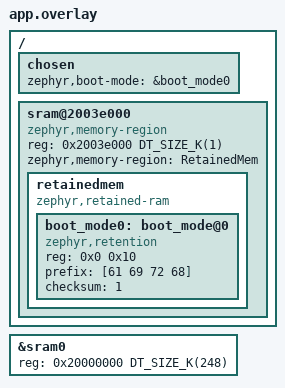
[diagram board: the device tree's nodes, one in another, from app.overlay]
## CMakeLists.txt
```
# SPDX-License-Identifier: Apache-2.0
cmake_minimum_required(VERSION 3.20.0)

find_package(Zephyr REQUIRED HINTS $ENV{ZEPHYR_BASE})
project(airhand)

target_sources(app PRIVATE src/main.c src/proto.c)
target_compile_definitions(app PRIVATE PROTO_VERSION="${APP_VERSION_STRING}")
```

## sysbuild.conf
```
SB_CONFIG_BOOTLOADER_MCUBOOT=y
SB_CONFIG_MCUBOOT_MODE_SWAP_USING_MOVE=y
# Anyone with the USB port can already flash the dongle, so a key adds no protection; MCUboot still checks a SHA-256.
SB_CONFIG_BOOT_SIGNATURE_TYPE_NONE=y
```

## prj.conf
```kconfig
# SPDX-License-Identifier: Apache-2.0
# The board brings up its USB serial port (CDC ACM) as the console at boot: requests come in there
# and printk sends the replies back the same way. Clients find the dongle by its USB product name.
CONFIG_CDC_ACM_SERIAL_MANUFACTURER_STRING="airhand"
CONFIG_CDC_ACM_SERIAL_PRODUCT_STRING="airhand"

CONFIG_BT=y
CONFIG_BT_PERIPHERAL=y
CONFIG_BT_MAX_CONN=1
CONFIG_BT_MAX_PAIRED=4
# With a full bond table a new pairing request gets no reply; Android shows that as a wrong PIN.
CONFIG_BT_KEYS_OVERWRITE_OLDEST=y
# A phone that forgot the dongle pairs again; otherwise the dongle keeps the old bond and Android shows a wrong PIN.
CONFIG_BT_SMP_ALLOW_UNAUTH_OVERWRITE=y
CONFIG_BT_DEVICE_NAME="airhand"
# Generic HID
CONFIG_BT_DEVICE_APPEARANCE=960

# The host starts security and PHY changes; starting them from both sides at once drops the link.
CONFIG_BT_GATT_AUTO_SEC_REQ=n
CONFIG_BT_AUTO_PHY_UPDATE=n

# Pointer and touch steps go out every 15 ms; at a slower interval they arrive in bursts, and iOS misreads a flick.
# Apple accepts a minimum equal to the maximum only at exactly 15 ms.
CONFIG_BT_PERIPHERAL_PREF_MIN_INT=12
CONFIG_BT_PERIPHERAL_PREF_MAX_INT=12
CONFIG_BT_PERIPHERAL_PREF_LATENCY=0
CONFIG_BT_PERIPHERAL_PREF_TIMEOUT=400

# use: only the chosen host may connect, and each host's name is read so use can take it.
CONFIG_BT_FILTER_ACCEPT_LIST=y
CONFIG_BT_GATT_CLIENT=y

# Just Works pairing; bonds survive a reboot, so the host reconnects by itself.
CONFIG_BT_SMP=y
CONFIG_BT_SETTINGS=y
CONFIG_SETTINGS=y
CONFIG_FLASH=y
CONFIG_FLASH_PAGE_LAYOUT=y
CONFIG_FLASH_MAP=y
CONFIG_NVS=y

CONFIG_BT_HIDS=y
CONFIG_BT_HIDS_INPUT_REP_MAX=5
CONFIG_BT_HIDS_OUTPUT_REP_MAX=0
CONFIG_BT_HIDS_FEATURE_REP_MAX=1
CONFIG_BT_HIDS_ATTR_MAX=48
CONFIG_BT_HIDS_MAX_CLIENT_COUNT=1
CONFIG_BT_HIDS_DEFAULT_PERM_RW_ENCRYPT=y
CONFIG_BT_GATT_UUID16_POOL_SIZE=64
CONFIG_BT_GATT_CHRC_POOL_SIZE=32
CONFIG_BT_CONN_CTX=y

CONFIG_BT_DIS=y
CONFIG_BT_DIS_PNP=y
CONFIG_BT_DIS_PNP_VID_SRC=2
CONFIG_BT_DIS_PNP_VID=0x1915
CONFIG_BT_DIS_PNP_PID=0xEEEE
CONFIG_BT_DIS_PNP_VER=0x0100

CONFIG_MAIN_STACK_SIZE=2048
CONFIG_SYSTEM_WORKQUEUE_STACK_SIZE=2048

# The chip id in the version reply.
CONFIG_HWINFO=y

# Updates through MCUboot: the update verb reboots into its update mode, and a client's version request keeps a new image.
CONFIG_RETAINED_MEM=y
CONFIG_RETAINED_MEM_ZEPHYR_RAM=y
CONFIG_RETAINED_MEM_NRF_GPREGRET=n
CONFIG_RETENTION=y
CONFIG_RETENTION_BOOT_MODE=y
CONFIG_REBOOT=y
CONFIG_STREAM_FLASH=y
CONFIG_IMG_MANAGER=y
CONFIG_MCUBOOT_IMG_MANAGER=y
CONFIG_WATCHDOG=y
CONFIG_RESET_ON_FATAL_ERROR=y
```

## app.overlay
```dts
/*
 * The boot mode that sends MCUboot into update mode, shared by the app and MCUboot. The nRF5 bootloader runs
 * between them on every reset and keeps its own flag in GPREGRET2, where the boot mode was lost, so it lives in
 * RAM that the nRF5 bootloader leaves alone: below its stack at the top of RAM and above its variables.
 */
/ {
	chosen {
		zephyr,boot-mode = &boot_mode0;
	};

	sram@2003e000 {
		compatible = "zephyr,memory-region", "mmio-sram";
		reg = <0x2003e000 DT_SIZE_K(1)>;
		zephyr,memory-region = "RetainedMem";
		status = "okay";

		retainedmem {
			compatible = "zephyr,retained-ram";
			status = "okay";
			#address-cells = <1>;
			#size-cells = <1>;

			boot_mode0: boot_mode@0 {
				compatible = "zephyr,retention";
				status = "okay";
				reg = <0x0 0x10>;
				prefix = [61 69 72 68];
				checksum = <1>;
			};
		};
	};
};

&sram0 {
	reg = <0x20000000 DT_SIZE_K(248)>;
};
```

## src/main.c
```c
/*
 * SPDX-License-Identifier: Apache-2.0
 *
 * airhand on an nRF52840: protocol lines arrive on the USB serial console, proto.c turns them into HID
 * reports, and this file sends those reports to the connected Bluetooth host over HID-over-GATT.
 * All output goes through say(), so an event line never lands inside a reply line.
 */

#include <errno.h>
#include <stdarg.h>
#include <string.h>
#include <zephyr/kernel.h>
#include <zephyr/device.h>
#include <zephyr/dfu/mcuboot.h>
#include <zephyr/drivers/hwinfo.h>
#include <zephyr/drivers/uart.h>
#include <zephyr/drivers/watchdog.h>
#include <zephyr/retention/bootmode.h>
#include <zephyr/settings/settings.h>
#include <zephyr/sys/printk.h>
#include <zephyr/sys/reboot.h>
#include <zephyr/usb/usbd.h>
#include <zephyr/bluetooth/bluetooth.h>
#include <zephyr/bluetooth/conn.h>
#include <zephyr/bluetooth/gatt.h>
#include <zephyr/bluetooth/uuid.h>
#include <bluetooth/services/hids.h>

#include "proto.h"

enum report_id { ID_KEYS = 1, ID_MOUSE, ID_CONSUMER, ID_POINTER, ID_TOUCH, ID_WIN8 };

#define SEND_TRIES 100
#define SEND_RETRY_MS 2
/* Lets the reply to update leave before USB goes. */
#define UPDATE_DELAY_MS 200
/* A soft reset with USB still attached can leave the port dead until a replug, so the host first sees it go. */
#define DETACH_MS 500
/* A new image that no client has spoken to by then is rolled back. */
#define TRIAL_S 60
/* Longer than the longest single wait in a verb: a 10 s hold. */
#define WATCHDOG_MS 30000

/*
 * Report descriptor, from the HID 1.11 specification and its usage tables. The order of the reports and
 * their sizes must match enum proto_report and the *_LEN constants in proto.h. A host caches this
 * descriptor when it pairs, so any change here means pairing again.
 */
static const uint8_t descriptor[] = {
	/* Keyboard as in HID 1.11 appendix B.1, without the LED output: modifiers, a reserved byte, 6 keys up to F24. */
	0x05, 0x01, 0x09, 0x06, 0xA1, 0x01, 0x85, ID_KEYS,
	0x05, 0x07, 0x19, 0xE0, 0x29, 0xE7, 0x15, 0x00, 0x25, 0x01, 0x75, 0x01, 0x95, 0x08, 0x81, 0x02,
	0x95, 0x01, 0x75, 0x08, 0x81, 0x01,
	0x95, 0x06, 0x75, 0x08, 0x15, 0x00, 0x25, 0x73, 0x05, 0x07, 0x19, 0x00, 0x29, 0x73, 0x81, 0x00,
	0xC0,

	/*
	 * Relative mouse: 3 buttons and 5 bits of padding, then X and Y moves, the wheel and horizontal pan,
	 * -127..127 each. iOS stops following the absolute pointer when a second mouse collection is added.
	 */
	0x05, 0x01, 0x09, 0x02, 0xA1, 0x01, 0x85, ID_MOUSE, 0x09, 0x01, 0xA1, 0x00,
	0x05, 0x09, 0x19, 0x01, 0x29, 0x03, 0x15, 0x00, 0x25, 0x01, 0x95, 0x03, 0x75, 0x01, 0x81, 0x02,
	0x95, 0x01, 0x75, 0x05, 0x81, 0x01,
	0x05, 0x01, 0x09, 0x30, 0x09, 0x31, 0x09, 0x38, 0x15, 0x81, 0x25, 0x7F, 0x75, 0x08, 0x95, 0x03, 0x81, 0x06,
	0x05, 0x0C, 0x0A, 0x38, 0x02, 0x95, 0x01, 0x81, 0x06,
	0xC0, 0xC0,

	/* Consumer control: one 16-bit usage up to 0x3FF, for keys such as AC Home and Volume Up. */
	0x05, 0x0C, 0x09, 0x01, 0xA1, 0x01, 0x85, ID_CONSUMER,
	0x15, 0x00, 0x26, 0xFF, 0x03, 0x19, 0x00, 0x2A, 0xFF, 0x03, 0x75, 0x10, 0x95, 0x01, 0x81, 0x00,
	0xC0,

	/* Absolute pointer: 3 buttons and 5 bits of padding, then X and Y as 0..32767 across the screen. */
	0x05, 0x01, 0x09, 0x02, 0xA1, 0x01, 0x85, ID_POINTER, 0x09, 0x01, 0xA1, 0x00,
	0x05, 0x09, 0x19, 0x01, 0x29, 0x03, 0x15, 0x00, 0x25, 0x01, 0x95, 0x03, 0x75, 0x01, 0x81, 0x02,
	0x95, 0x01, 0x75, 0x05, 0x81, 0x01,
	0x05, 0x01, 0x09, 0x30, 0x09, 0x31, 0x15, 0x00, 0x26, 0xFF, 0x7F, 0x75, 0x10, 0x95, 0x02, 0x81, 0x02,
	0xC0, 0xC0,

	/*
	 * Touch screen with one finger: tip switch and in range, then contact id, X and Y as 0..32767, and contact
	 * count. The contact id makes Linux bind hid-multitouch, so Android gets a direct touch screen.
	 */
	0x05, 0x0D, 0x09, 0x04, 0xA1, 0x01, 0x85, ID_TOUCH, 0x09, 0x22, 0xA1, 0x02,
	0x09, 0x42, 0x09, 0x32, 0x15, 0x00, 0x25, 0x01, 0x75, 0x01, 0x95, 0x02, 0x81, 0x02,
	0x95, 0x06, 0x81, 0x01,
	0x09, 0x51, 0x25, 0x7F, 0x75, 0x08, 0x95, 0x01, 0x81, 0x02,
	0x05, 0x01, 0x09, 0x30, 0x09, 0x31, 0x26, 0xFF, 0x7F, 0x75, 0x10, 0x95, 0x02, 0x81, 0x02,
	0xC0,
	0x05, 0x0D, 0x09, 0x54, 0x25, 0x7F, 0x75, 0x08, 0x95, 0x01, 0x81, 0x02,
	/*
	 * Vendor feature 0xFF0000C6, one byte: Linux then takes the touch screen as a Windows 8 one, whose class
	 * keeps the mouse, so Android shows a cursor. Without it hid-multitouch drops every mouse collection.
	 */
	0x85, ID_WIN8, 0x06, 0x00, 0xFF, 0x09, 0xC6, 0x26, 0xFF, 0x00, 0x75, 0x08, 0x95, 0x01, 0xB1, 0x02,
	0xC0,
};

static const struct {
	uint8_t id;
	uint8_t size;
} reports[] = {
	[REP_KEYS] = {ID_KEYS, KEYS_LEN},
	[REP_MOUSE] = {ID_MOUSE, MOUSE_LEN},
	[REP_CONSUMER] = {ID_CONSUMER, CONSUMER_LEN},
	[REP_POINTER] = {ID_POINTER, POINTER_LEN},
	[REP_TOUCH] = {ID_TOUCH, TOUCH_LEN},
};

BT_HIDS_DEF(hid_service, KEYS_LEN, MOUSE_LEN, CONSUMER_LEN, POINTER_LEN, TOUCH_LEN, WIN8_LEN);

static K_MUTEX_DEFINE(host_lock);
static struct bt_conn *host;
static uint16_t interval_units;
static K_MUTEX_DEFINE(say_lock);
static int service_err;
static const struct device *const watchdog = DEVICE_DT_GET(DT_NODELABEL(wdt0));
static int watchdog_channel = -1;

static void say(const char *fmt, ...)
{
	char line[PROTO_REPLY_MAX + 16];
	va_list args;

	va_start(args, fmt);
	vsnprintk(line, sizeof(line), fmt, args);
	va_end(args);
	k_mutex_lock(&say_lock, K_FOREVER);
	printk("%s\n", line);
	k_mutex_unlock(&say_lock);
}

static struct bt_conn *host_conn(void)
{
	struct bt_conn *conn;

	k_mutex_lock(&host_lock, K_FOREVER);
	conn = host ? bt_conn_ref(host) : NULL;
	k_mutex_unlock(&host_lock);
	return conn;
}

static void set_host(struct bt_conn *conn)
{
	k_mutex_lock(&host_lock, K_FOREVER);
	if (host) {
		bt_conn_unref(host);
	}
	host = conn ? bt_conn_ref(conn) : NULL;
	k_mutex_unlock(&host_lock);
}

static const struct bt_data adv_data[] = {
	BT_DATA_BYTES(BT_DATA_FLAGS, BT_LE_AD_GENERAL | BT_LE_AD_NO_BREDR),
	BT_DATA_BYTES(BT_DATA_GAP_APPEARANCE, CONFIG_BT_DEVICE_APPEARANCE & 0xFF, CONFIG_BT_DEVICE_APPEARANCE >> 8),
	BT_DATA_BYTES(BT_DATA_UUID16_ALL, BT_UUID_16_ENCODE(BT_UUID_HIDS_VAL)),
};

static const struct bt_data scan_data[] = {
	BT_DATA(BT_DATA_NAME_COMPLETE, CONFIG_BT_DEVICE_NAME, sizeof(CONFIG_BT_DEVICE_NAME) - 1),
};

/* The host that use chose; while set, only it may connect. Guarded by host_lock. */
static bt_addr_le_t chosen;
static bool has_chosen;

static bool get_chosen(bt_addr_le_t *out)
{
	bool set;

	k_mutex_lock(&host_lock, K_FOREVER);
	set = has_chosen;
	*out = chosen;
	k_mutex_unlock(&host_lock);
	return set;
}

/* The accept list can change only while advertising is off, so this work item owns both. */
static void start_advertising(struct k_work *work)
{
	ARG_UNUSED(work);
	bt_addr_le_t only;
	bool filter = get_chosen(&only);
	int err;

	bt_le_adv_stop();
	bt_le_filter_accept_list_clear();
	if (filter) {
		bt_le_filter_accept_list_add(&only);
	}
	err = bt_le_adv_start(filter ? BT_LE_ADV_PARAM(BT_LE_ADV_OPT_CONN | BT_LE_ADV_OPT_FILTER_CONN,
						      BT_GAP_ADV_FAST_INT_MIN_2, BT_GAP_ADV_FAST_INT_MAX_2, NULL)
				     : BT_LE_ADV_CONN_FAST_2,
			      adv_data, ARRAY_SIZE(adv_data), scan_data, ARRAY_SIZE(scan_data));

	if (err) {
		say("evt ready adv=failed err=%d", err);
	} else {
		say("evt ready adv=on");
	}
}

/* Advertising cannot restart from inside the disconnected callback. */
static K_WORK_DEFINE(advertising, start_advertising);

static void on_connected(struct bt_conn *conn, uint8_t err)
{
	if (err) {
		say("evt connect_failed hci=0x%02x", err);
		k_work_submit(&advertising);
		return;
	}
	bt_addr_le_t only;

	if (get_chosen(&only) && !bt_addr_le_eq(bt_conn_get_dst(conn), &only)) {
		say("evt refused not_chosen");
		bt_conn_disconnect(conn, BT_HCI_ERR_REMOTE_USER_TERM_CONN);
		return;
	}
	bt_hids_connected(&hid_service, conn);
	set_host(conn);
	say("evt connected");
}

static void on_disconnected(struct bt_conn *conn, uint8_t reason)
{
	struct bt_conn *current = host_conn();

	if (current != conn) {
		if (current) {
			bt_conn_unref(current);
		}
		k_work_submit(&advertising);
		return;
	}
	bt_conn_unref(current);
	bt_hids_disconnected(&hid_service, conn);
	set_host(NULL);
	say("evt disconnected reason=0x%02x", reason);
	k_work_submit(&advertising);
}

/* Host names, read from each host's GAP Device Name once it is encrypted, so use can take a name. */
static struct {
	bt_addr_le_t addr;
	char name[PROTO_NAME_MAX + 1];
} names[CONFIG_BT_MAX_PAIRED];
BUILD_ASSERT(PROTO_HOSTS_MAX == CONFIG_BT_MAX_PAIRED);
static K_MUTEX_DEFINE(names_lock);

static int names_set(const char *key, size_t len, settings_read_cb read, void *arg)
{
	if (strcmp(key, "names") != 0 || len != sizeof(names)) {
		return -ENOENT;
	}
	return read(arg, names, sizeof(names)) == sizeof(names) ? 0 : -EIO;
}

SETTINGS_STATIC_HANDLER_DEFINE(airhand, "airhand", NULL, names_set, NULL, NULL);

static void save_names(struct k_work *work)
{
	ARG_UNUSED(work);
	k_mutex_lock(&names_lock, K_FOREVER);
	int err = settings_save_one("airhand/names", names, sizeof(names));

	k_mutex_unlock(&names_lock);
	if (err) {
		say("evt names_save_failed err=%d", err);
	}
}

static K_WORK_DEFINE(names_saving, save_names);

static bool is_bonded(const bt_addr_le_t *addr)
{
	return bt_le_bond_exists(BT_ID_DEFAULT, addr);
}

static void remember_name(const bt_addr_le_t *addr, const uint8_t *data, uint16_t len)
{
	size_t slot = 0;

	k_mutex_lock(&names_lock, K_FOREVER);
	for (size_t i = 0; i < ARRAY_SIZE(names); i++) {
		if (bt_addr_le_eq(&names[i].addr, addr)) {
			slot = i;
			break;
		}
		if (!is_bonded(&names[i].addr)) {
			slot = i;
		}
	}
	len = MIN(len, PROTO_NAME_MAX);
	names[slot].addr = *addr;
	memcpy(names[slot].name, data, len);
	names[slot].name[len] = '\0';
	k_mutex_unlock(&names_lock);
	k_work_submit(&names_saving);
}

static void name_of(const bt_addr_le_t *addr, char *out, size_t len)
{
	out[0] = '\0';
	k_mutex_lock(&names_lock, K_FOREVER);
	for (size_t i = 0; i < ARRAY_SIZE(names); i++) {
		if (bt_addr_le_eq(&names[i].addr, addr)) {
			strncpy(out, names[i].name, len - 1);
			out[len - 1] = '\0';
		}
	}
	k_mutex_unlock(&names_lock);
}

static uint8_t on_name(struct bt_conn *conn, uint8_t err, struct bt_gatt_read_params *params, const void *data,
		       uint16_t len)
{
	ARG_UNUSED(params);
	if (!err && data && len) {
		remember_name(bt_conn_get_dst(conn), data, len);
	}
	return BT_GATT_ITER_STOP;
}

static const struct bt_uuid_16 device_name = BT_UUID_INIT_16(BT_UUID_GAP_DEVICE_NAME_VAL);

static void read_name(struct bt_conn *conn)
{
	static struct bt_gatt_read_params params = {
		.func = on_name,
		.handle_count = 0,
		.by_uuid = {.uuid = &device_name.uuid, .start_handle = 0x0001, .end_handle = 0xffff},
	};
	int err = bt_gatt_read(conn, &params);

	if (err) {
		say("evt name_read_failed err=%d", err);
	}
}

static void on_security(struct bt_conn *conn, bt_security_t level, enum bt_security_err err)
{
	if (err) {
		say("evt security_failed sec=%u err=%d", level, err);
	} else {
		say("evt security sec=%u", level);
		if (level >= BT_SECURITY_L2 && bt_le_bond_exists(BT_ID_DEFAULT, bt_conn_get_dst(conn))) {
			read_name(conn);
		}
	}
}

static void on_params(struct bt_conn *conn, uint16_t interval, uint16_t latency, uint16_t timeout)
{
	ARG_UNUSED(conn);
	interval_units = interval;
	say("evt params interval_ms=%u.%02u latency=%u timeout_ms=%u", interval * 125 / 100, interval * 125 % 100,
	    latency, timeout * 10);
}

BT_CONN_CB_DEFINE(link_events) = {
	.connected = on_connected,
	.disconnected = on_disconnected,
	.security_changed = on_security,
	.le_param_updated = on_params,
};

static void on_paired(struct bt_conn *conn, bool bonded)
{
	ARG_UNUSED(conn);
	say("evt paired bonded=%s", bonded ? "yes" : "no");
}

static void on_pairing_failed(struct bt_conn *conn, enum bt_security_err reason)
{
	ARG_UNUSED(conn);
	say("evt pairing_failed reason=%d", reason);
}

static struct bt_conn_auth_info_cb pairing_events = {
	.pairing_complete = on_paired,
	.pairing_failed = on_pairing_failed,
};

static int start_hid_service(void)
{
	struct bt_hids_init_param params = {
		.rep_map = {.data = descriptor, .size = sizeof(descriptor)},
		.info = {.bcd_hid = 0x0101, .flags = BT_HIDS_REMOTE_WAKE | BT_HIDS_NORMALLY_CONNECTABLE},
	};

	for (size_t i = 0; i < ARRAY_SIZE(reports); i++) {
		params.inp_rep_group_init.reports[i].id = reports[i].id;
		params.inp_rep_group_init.reports[i].size = reports[i].size;
	}
	params.inp_rep_group_init.cnt = ARRAY_SIZE(reports);
	params.feat_rep_group_init.reports[0].id = ID_WIN8;
	params.feat_rep_group_init.reports[0].size = WIN8_LEN;
	params.feat_rep_group_init.cnt = 1;
	return bt_hids_init(&hid_service, &params);
}

static int host_ready(void)
{
	struct bt_conn *conn = host_conn();

	if (!conn) {
		return -ENOTCONN;
	}
	bt_security_t level = bt_conn_get_security(conn);

	bt_conn_unref(conn);
	return level < BT_SECURITY_L2 ? -EACCES : 0;
}

static void feed(void)
{
	if (watchdog_channel >= 0) {
		wdt_feed(watchdog, watchdog_channel);
	}
}

static void wait_ms(uint32_t ms)
{
	k_msleep(ms);
	feed();
}

static int send_report(enum proto_report report, const uint8_t *data, size_t len)
{
	struct bt_conn *conn = host_conn();
	int err = -ENOTCONN;

	if (!conn) {
		return err;
	}
	/* Reports that come faster than the connection interval use up the stack's buffers. */
	for (int try = 0; try < SEND_TRIES; try++) {
		err = bt_hids_inp_rep_send(&hid_service, conn, report, data, len, NULL);
		if (err != -ENOMEM && err != -EAGAIN) {
			break;
		}
		wait_ms(SEND_RETRY_MS);
	}
	bt_conn_unref(conn);
	return err;
}

/* A new image that hangs is reset, and MCUboot, which feeds the watchdog while it swaps, rolls it back. */
static void start_watchdog(void)
{
	const struct wdt_timeout_cfg timeout = {.window.max = WATCHDOG_MS, .flags = WDT_FLAG_RESET_SOC};

	watchdog_channel = wdt_install_timeout(watchdog, &timeout);
	if (watchdog_channel < 0 || wdt_setup(watchdog, WDT_OPT_PAUSE_HALTED_BY_DBG) != 0) {
		say("evt watchdog_failed err=%d", watchdog_channel);
		watchdog_channel = -1;
	}
}

static void restart(struct k_work *work)
{
	ARG_UNUSED(work);
	STRUCT_SECTION_FOREACH(usbd_context, usb) {
		usbd_disable(usb);
	}
	k_msleep(DETACH_MS);
	sys_reboot(SYS_REBOOT_COLD);
}

static K_WORK_DELAYABLE_DEFINE(update_restart, restart);
static K_WORK_DELAYABLE_DEFINE(trial_end, restart);

static int enter_update(void)
{
	int err = bootmode_set(BOOT_MODE_TYPE_BOOTLOADER);

	if (!err) {
		k_work_schedule(&update_restart, K_MSEC(UPDATE_DELAY_MS));
	}
	return err;
}

static void confirm_image(void)
{
	if (mcuboot_swap_type() != BOOT_SWAP_TYPE_REVERT) {
		return;
	}
	int err = boot_write_img_confirmed();

	if (err) {
		say("evt confirm_failed err=%d", err);
	} else {
		k_work_cancel_delayable(&trial_end);
		say("evt confirmed");
	}
}

static int forget_hosts(void)
{
	k_mutex_lock(&host_lock, K_FOREVER);
	has_chosen = false;
	k_mutex_unlock(&host_lock);
	k_mutex_lock(&names_lock, K_FOREVER);
	memset(names, 0, sizeof(names));
	k_mutex_unlock(&names_lock);
	k_work_submit(&names_saving);
	return bt_unpair(BT_ID_DEFAULT, BT_ADDR_LE_ANY);
}

struct bonds {
	int count;
	bt_addr_le_t addr[PROTO_HOSTS_MAX];
};

static void add_bond(const struct bt_bond_info *info, void *data)
{
	struct bonds *bonds = data;

	if (bonds->count < PROTO_HOSTS_MAX) {
		bonds->addr[bonds->count++] = info->addr;
	}
}

static int index_of(const struct bonds *bonds, const bt_addr_le_t *addr)
{
	for (int i = 0; i < bonds->count; i++) {
		if (bt_addr_le_eq(&bonds->addr[i], addr)) {
			return i;
		}
	}
	return -1;
}

static void list_hosts(struct proto_hosts *out)
{
	struct bonds bonds = {0};
	struct bt_conn *conn = host_conn();
	bt_addr_le_t only;

	bt_foreach_bond(BT_ID_DEFAULT, add_bond, &bonds);
	out->count = bonds.count;
	for (int i = 0; i < bonds.count; i++) {
		bt_addr_to_str(&bonds.addr[i].a, out->list[i].addr, sizeof(out->list[i].addr));
		name_of(&bonds.addr[i], out->list[i].name, sizeof(out->list[i].name));
	}
	out->chosen = get_chosen(&only) ? index_of(&bonds, &only) : -1;
	out->connected = conn ? index_of(&bonds, bt_conn_get_dst(conn)) : -1;
	if (conn) {
		bt_conn_unref(conn);
	}
}

static int use_host(int index)
{
	struct bonds bonds = {0};
	struct bt_conn *conn = host_conn();

	bt_foreach_bond(BT_ID_DEFAULT, add_bond, &bonds);
	if (index >= bonds.count) {
		if (conn) {
			bt_conn_unref(conn);
		}
		return -ENOENT;
	}
	k_mutex_lock(&host_lock, K_FOREVER);
	has_chosen = index >= 0;
	if (has_chosen) {
		chosen = bonds.addr[index];
	}
	k_mutex_unlock(&host_lock);
	if (!conn) {
		k_work_submit(&advertising);
		return 0;
	}
	if (index >= 0 && !bt_addr_le_eq(bt_conn_get_dst(conn), &bonds.addr[index])) {
		bt_conn_disconnect(conn, BT_HCI_ERR_REMOTE_USER_TERM_CONN);
	}
	bt_conn_unref(conn);
	return 0;
}

static void describe(char *out, size_t len)
{
	struct bt_conn *conn = host_conn();
	unsigned int level = 0;

	if (conn) {
		level = bt_conn_get_security(conn);
		bt_conn_unref(conn);
	}
	snprintk(out, len, "conn=%s sec=%u interval_ms=%u hid_init=%d uptime_s=%u", conn ? "yes" : "no", level,
		 interval_units * 125 / 100, service_err, (unsigned int)(k_uptime_get() / 1000));
}

static void read_chip_id(char *out, size_t len)
{
	uint8_t raw[8];
	ssize_t count = hwinfo_get_device_id(raw, sizeof(raw));
	size_t at = 0;

	out[0] = '\0';
	for (ssize_t i = 0; i < count && at + 2 < len; i++) {
		at += snprintk(out + at, len - at, "%02X", raw[i]);
	}
}

/* A longer line is cut at PROTO_LINE_MAX bytes, which proto_handle still refuses as too long. */
static const char *next_line(const struct device *console)
{
	static char line[PROTO_LINE_MAX + 1];
	size_t len = 0;
	unsigned char c;

	for (;;) {
		feed();
		if (uart_poll_in(console, &c) != 0) {
			k_msleep(1);
		} else if (c == '\n') {
			line[len] = '\0';
			return line;
		} else if (c != '\r' && len < PROTO_LINE_MAX) {
			line[len++] = c;
		}
	}
}

int main(void)
{
	const struct device *console = DEVICE_DT_GET(DT_CHOSEN(zephyr_console));
	static char chip_id[17];
	static struct proto_ops ops = {
		.ready = host_ready,
		.send = send_report,
		.sleep_ms = wait_ms,
		.unpair = forget_hosts,
		.status = describe,
		.confirm = confirm_image,
		.update = enter_update,
		.chip_id = chip_id,
		.hosts = list_hosts,
		.use = use_host,
	};

	start_watchdog();
	if (mcuboot_swap_type() == BOOT_SWAP_TYPE_REVERT) {
		k_work_schedule(&trial_end, K_SECONDS(TRIAL_S));
	}
	read_chip_id(chip_id, sizeof(chip_id));
	service_err = start_hid_service();
	ops.hid_init_err = service_err;
	bt_conn_auth_info_cb_register(&pairing_events);

	int err = bt_enable(NULL);

	if (err) {
		say("evt bt_failed err=%d", err);
	} else {
		settings_load();
		k_work_submit(&advertising);
	}

	for (;;) {
		const char *reply = proto_handle(&ops, next_line(console));

		if (*reply) {
			say("%s", reply);
		}
	}
}
```

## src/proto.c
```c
#include "proto.h"

#include <ctype.h>
#include <errno.h>
#include <stdbool.h>
#include <stdio.h>
#include <stdlib.h>
#include <string.h>

#define MOD_CTRL  0x01
#define MOD_SHIFT 0x02
#define MOD_ALT   0x04
#define MOD_GUI   0x08

/* iOS AssistiveTouch applies pointer reports about one connection interval late: it presses where its cursor was,
 * and a move sent right after a release turns a tap into a drag. */
#define SETTLE_MS     100
#define TAP_HOLD_MS   60
#define SWIPE_STEP_MS 15
#define WHEEL_STEP_MS 15
#define SWIPE_MAX_STEPS 300
#define CLICK_GAP_MS  80
#define MAX_CLICKS    5
#define MAX_HOLD_MS   10000
/* Linux lifts a Windows 8 touch screen's contact after 100 ms with no report. */
#define CONTACT_QUIET_MS 80
#define RESULT_SLOTS 8
#define ID_MAX 10

struct key {
	uint8_t mod;
	uint8_t code;
};

struct named {
	const char *name;
	uint8_t value;
};

static const struct named key_names[] = {
	{"enter", 40}, {"return", 40}, {"escape", 41}, {"esc", 41}, {"backspace", 42}, {"tab", 43},
	{"space", 44}, {"insert", 73}, {"home", 74}, {"pageup", 75}, {"delete", 76}, {"end", 77},
	{"pagedown", 78}, {"right", 79}, {"left", 80}, {"down", 81}, {"up", 82},
	{"f1", 58}, {"f2", 59}, {"f3", 60}, {"f4", 61}, {"f5", 62}, {"f6", 63},
	{"f7", 64}, {"f8", 65}, {"f9", 66}, {"f10", 67}, {"f11", 68}, {"f12", 69},
	{"printscreen", 70}, {"scrolllock", 71}, {"pause", 72}, {"numlock", 83},
	{"numpaddivide", 84}, {"numpadmultiply", 85}, {"numpadminus", 86}, {"numpadplus", 87},
	{"numpadenter", 88}, {"numpad1", 89}, {"numpad2", 90}, {"numpad3", 91}, {"numpad4", 92},
	{"numpad5", 93}, {"numpad6", 94}, {"numpad7", 95}, {"numpad8", 96}, {"numpad9", 97},
	{"numpad0", 98}, {"numpaddecimal", 99}, {"numpadperiod", 99}, {"capslock", 57},
	{"menu", 101}, {"application", 101}, {"f13", 104}, {"f14", 105}, {"f15", 106}, {"f16", 107},
	{"f17", 108}, {"f18", 109}, {"f19", 110}, {"f20", 111}, {"f21", 112}, {"f22", 113}, {"f23", 114},
	{"f24", 115},
};

static const struct named modifier_names[] = {
	{"ctrl", MOD_CTRL}, {"control", MOD_CTRL}, {"shift", MOD_SHIFT}, {"alt", MOD_ALT},
	{"option", MOD_ALT}, {"cmd", MOD_GUI}, {"command", MOD_GUI}, {"gui", MOD_GUI},
	{"meta", MOD_GUI}, {"win", MOD_GUI},
};

static const struct {
	const char *name;
	uint16_t usage;
} media_names[] = {
	{"home", 0x223}, {"back", 0x224}, {"search", 0x221}, {"volup", 0xE9}, {"voldown", 0xEA},
	{"mute", 0xE2}, {"playpause", 0xCD}, {"next", 0xB5}, {"previous", 0xB6}, {"stop", 0xB7},
	{"brightnessup", 0x6F}, {"brightnessdown", 0x70},
};

static const struct named button_names[] = {{"left", 1}, {"right", 2}, {"middle", 4}};

/* US layout: the characters on the keys from 0x2D to 0x38; 0x32 is the non-US hash key, which a US layout lacks. */
static const char punct[] = "-=[]\\\x01;'`,./";
static const char punct_shifted[] = "_+{}|\x01:\"~<>?";
static const char digit_shifted[] = "!@#$%^&*()";

static struct {
	char id[ID_MAX + 1];
	char reply[PROTO_REPLY_MAX];
} results[RESULT_SLOTS];
static unsigned int next_slot;

static uint16_t pointer_x, pointer_y;
/* Android reads the absolute pointer as a relative mouse, so it gets touches instead. */
static bool touch_mode;
static bool touching;
static char reply[PROTO_REPLY_MAX];

struct run {
	const struct proto_ops *ops;
	int done;
	int total;
	int err;
};

static bool char_key(char c, struct key *k)
{
	const char *p;

	k->mod = 0;
	if (c >= 'a' && c <= 'z') {
		k->code = 4 + (c - 'a');
	} else if (c >= 'A' && c <= 'Z') {
		k->mod = MOD_SHIFT;
		k->code = 4 + (c - 'A');
	} else if (c >= '1' && c <= '9') {
		k->code = 30 + (c - '1');
	} else if (c == '0') {
		k->code = 39;
	} else if (c == '\n') {
		k->code = 40;
	} else if (c == '\t') {
		k->code = 43;
	} else if (c == ' ') {
		k->code = 44;
	} else if (c > 0x01 && (p = strchr(digit_shifted, c)) != NULL) {
		k->mod = MOD_SHIFT;
		k->code = 30 + (p - digit_shifted);
	} else if (c > 0x01 && (p = strchr(punct, c)) != NULL) {
		k->code = 0x2D + (p - punct);
	} else if (c > 0x01 && (p = strchr(punct_shifted, c)) != NULL) {
		k->mod = MOD_SHIFT;
		k->code = 0x2D + (p - punct_shifted);
	} else {
		return false;
	}
	return true;
}

static int lookup(const struct named *table, size_t count, const char *name)
{
	for (size_t i = 0; i < count; i++) {
		if (strcmp(table[i].name, name) == 0) {
			return table[i].value;
		}
	}
	return -1;
}

#define LOOKUP(table, name) lookup(table, sizeof(table) / sizeof(table[0]), name)

static bool parse_combo(const char *combo, struct key *k)
{
	char buf[48];
	char *part, *save = NULL;
	char *last = NULL;
	uint8_t mod = 0;

	if (strlen(combo) >= sizeof(buf) || !*combo) {
		return false;
	}
	strcpy(buf, combo);
	for (char *c = buf; *c; c++) {
		*c = tolower((unsigned char)*c);
	}
	for (part = strtok_r(buf, "+", &save); part; part = strtok_r(NULL, "+", &save)) {
		if (last) {
			int m = LOOKUP(modifier_names, last);

			if (m < 0) {
				return false;
			}
			mod |= m;
		}
		last = part;
	}
	if (!last) {
		return false;
	}
	int named = LOOKUP(key_names, last);
	int alone = LOOKUP(modifier_names, last);

	if (named >= 0) {
		k->mod = mod;
		k->code = named;
		return true;
	}
	if (strlen(last) == 1 && char_key(last[0], k)) {
		k->mod |= mod;
		return true;
	}
	if (alone >= 0) {
		k->mod = mod | alone;
		k->code = 0;
		return true;
	}
	return false;
}

/* Decodes a JSON string into ASCII; false on bad JSON or a character outside ASCII. */
static bool decode_json(const char *in, char *out, size_t out_len, bool *unsupported)
{
	size_t n = 0;

	*unsupported = false;
	if (*in++ != '"') {
		return false;
	}
	while (*in && *in != '"') {
		unsigned int c = (unsigned char)*in++;

		if (c == '\\') {
			char e = *in++;

			switch (e) {
			case '"': c = '"'; break;
			case '\\': c = '\\'; break;
			case '/': c = '/'; break;
			case 'b': c = '\b'; break;
			case 'f': c = '\f'; break;
			case 'n': c = '\n'; break;
			case 'r': c = '\r'; break;
			case 't': c = '\t'; break;
			case 'u': {
				char hex[5] = {0};

				for (int i = 0; i < 4; i++) {
					if (!isxdigit((unsigned char)in[i])) {
						return false;
					}
					hex[i] = in[i];
				}
				in += 4;
				c = strtoul(hex, NULL, 16);
				break;
			}
			default:
				return false;
			}
		}
		if (c > 0x7F) {
			*unsupported = true;
			c = '?';
		}
		if (n + 1 >= out_len) {
			return false;
		}
		out[n++] = c;
	}
	if (*in != '"' || in[1] != '\0') {
		return false;
	}
	out[n] = '\0';
	return true;
}

static bool parse_fraction(char **p, uint16_t *out)
{
	char *end;
	double v = strtod(*p, &end);

	if (end == *p || v < 0.0 || v > 1.0) {
		return false;
	}
	*p = end;
	*out = (uint16_t)(v * POINTER_MAX + 0.5);
	return true;
}

static bool parse_long(char **p, long *out)
{
	char *end;

	*out = strtol(*p, &end, 10);
	if (end == *p) {
		return false;
	}
	*p = end;
	return true;
}

static bool at_end(const char *p)
{
	while (*p == ' ') {
		p++;
	}
	return *p == '\0';
}

static void put(struct run *r, enum proto_report report, const uint8_t *data, size_t len)
{
	if (r->err) {
		return;
	}
	int err = r->ops->send(report, data, len);

	if (err) {
		r->err = err;
		return;
	}
	r->done++;
}

static void pointer(struct run *r, uint8_t buttons, uint16_t x, uint16_t y)
{
	uint8_t rep[POINTER_LEN] = {buttons, x & 0xFF, x >> 8, y & 0xFF, y >> 8};

	put(r, REP_POINTER, rep, sizeof(rep));
	if (!r->err) {
		pointer_x = x;
		pointer_y = y;
	}
}

static uint8_t held[TOUCH_LEN];

static void contact(struct run *r, bool down, uint16_t x, uint16_t y)
{
	uint8_t rep[TOUCH_LEN] = {down ? 0x03 : 0x00, 0, x & 0xFF, x >> 8, y & 0xFF, y >> 8, 1};

	put(r, REP_TOUCH, rep, sizeof(rep));
	if (!r->err) {
		touching = down;
		memcpy(held, rep, sizeof(held));
	}
}

/* A touch screen has no hover and one button, so in touch mode a move with no button sends nothing. */
static void point(struct run *r, uint8_t buttons, uint16_t x, uint16_t y)
{
	if (!touch_mode) {
		pointer(r, buttons, x, y);
		return;
	}
	if (buttons || touching) {
		contact(r, buttons != 0, x, y);
	} else if (!r->err) {
		r->done++;
	}
	pointer_x = x;
	pointer_y = y;
}

static void press_key(struct run *r, struct key k)
{
	uint8_t down[KEYS_LEN] = {k.mod, 0, k.code};
	uint8_t up[KEYS_LEN] = {0};

	put(r, REP_KEYS, down, sizeof(down));
	put(r, REP_KEYS, up, sizeof(up));
}

static void consumer(struct run *r, uint16_t usage)
{
	uint8_t rep[CONSUMER_LEN] = {usage & 0xFF, usage >> 8};

	put(r, REP_CONSUMER, rep, sizeof(rep));
}

static void wait_ms(struct run *r, uint32_t ms)
{
	while (!r->err && touching && ms > CONTACT_QUIET_MS) {
		r->ops->sleep_ms(CONTACT_QUIET_MS / 2);
		ms -= CONTACT_QUIET_MS / 2;
		r->err = r->ops->send(REP_TOUCH, held, sizeof(held));
	}
	if (!r->err) {
		r->ops->sleep_ms(ms);
	}
}

/* The checks every report command passes before its first report; NULL when it may run. */
static const char *refusal(const struct proto_ops *ops)
{
	static char why[48];

	if (ops->hid_init_err) {
		snprintf(why, sizeof(why), "err hid init failed %d", ops->hid_init_err);
		return why;
	}
	int ready = ops->ready();

	if (ready == -ENOTCONN) {
		return "err not connected";
	}
	if (ready == -EACCES) {
		return "err not secure";
	}
	if (ready) {
		snprintf(why, sizeof(why), "err not ready %d", ready);
		return why;
	}
	return NULL;
}

static const char *outcome(const struct run *r)
{
	if (!r->err) {
		return "ok";
	}
	if (r->done == 0) {
		snprintf(reply, sizeof(reply), "err %s %d", r->err == -ENOMEM ? "busy" : "failed", r->err);
	} else {
		snprintf(reply, sizeof(reply), "err partial %d/%d failed %d", r->done, r->total, r->err);
	}
	return reply;
}

/* Optional trailing words: a button name, then a count of clicks. */
static bool parse_button(char **p, uint8_t *button)
{
	char word[8];
	int n = 0;

	*button = 1;
	while (**p == ' ') {
		(*p)++;
	}
	while (isalpha((unsigned char)**p) && n < (int)sizeof(word) - 1) {
		word[n++] = *(*p)++;
	}
	if (n == 0) {
		return true;
	}
	word[n] = '\0';
	int found = LOOKUP(button_names, word);

	if (found < 0) {
		return false;
	}
	*button = found;
	return true;
}

static void click(struct run *r, uint8_t button, uint16_t x, uint16_t y, uint32_t hold_ms)
{
	point(r, button, x, y);
	wait_ms(r, hold_ms);
	point(r, 0, x, y);
}

static const char *cmd_tap(struct run *r, char *args)
{
	uint16_t x, y;
	uint8_t button;
	long count = 1;

	if (!parse_fraction(&args, &x) || !parse_fraction(&args, &y) || !parse_button(&args, &button)) {
		return "err bad args";
	}
	if (!at_end(args) && (!parse_long(&args, &count) || count < 1 || count > MAX_CLICKS)) {
		return "err bad args";
	}
	if (!at_end(args)) {
		return "err bad args";
	}
	r->total = 1 + 2 * count;
	point(r, 0, x, y);
	wait_ms(r, SETTLE_MS);
	for (long i = 0; i < count; i++) {
		if (i) {
			wait_ms(r, CLICK_GAP_MS);
		}
		click(r, button, x, y, TAP_HOLD_MS);
	}
	wait_ms(r, SETTLE_MS);
	return outcome(r);
}

static const char *cmd_hold(struct run *r, char *args)
{
	uint16_t x, y;
	long ms;
	uint8_t button;

	if (!parse_fraction(&args, &x) || !parse_fraction(&args, &y) || !parse_long(&args, &ms) || ms < 0 ||
	    ms > MAX_HOLD_MS || !parse_button(&args, &button) || !at_end(args)) {
		return "err bad args";
	}
	r->total = 3;
	point(r, 0, x, y);
	wait_ms(r, SETTLE_MS);
	click(r, button, x, y, ms);
	wait_ms(r, SETTLE_MS);
	return outcome(r);
}

static const char *cmd_move(struct run *r, char *args)
{
	uint16_t x, y;

	if (!parse_fraction(&args, &x) || !parse_fraction(&args, &y) || !at_end(args)) {
		return "err bad args";
	}
	r->total = 1;
	point(r, 0, x, y);
	return outcome(r);
}

/* x1 y1 x2 y2 ms [hold_ms]: hold_ms keeps the button down before the move starts, as a drag that begins with a long press. */
static const char *cmd_swipe(struct run *r, char *args)
{
	uint16_t x1, y1, x2, y2;
	long ms, hold = 0;

	if (!parse_fraction(&args, &x1) || !parse_fraction(&args, &y1) || !parse_fraction(&args, &x2) ||
	    !parse_fraction(&args, &y2) || !parse_long(&args, &ms) || ms < 0) {
		return "err bad args";
	}
	if (!at_end(args) && (!parse_long(&args, &hold) || hold < 0 || hold > MAX_HOLD_MS)) {
		return "err bad args";
	}
	if (!at_end(args)) {
		return "err bad args";
	}
	long steps = ms / SWIPE_STEP_MS;

	steps = steps < 1 ? 1 : steps > SWIPE_MAX_STEPS ? SWIPE_MAX_STEPS : steps;
	r->total = 3 + steps;
	point(r, 0, x1, y1);
	wait_ms(r, SETTLE_MS);
	point(r, 1, x1, y1);
	wait_ms(r, hold);
	for (long i = 1; i <= steps; i++) {
		wait_ms(r, ms / steps);
		point(r, 1, x1 + ((long)x2 - x1) * i / steps, y1 + ((long)y2 - y1) * i / steps);
	}
	point(r, 0, x2, y2);
	wait_ms(r, SETTLE_MS);
	return outcome(r);
}

static int8_t clamp8(long v)
{
	return v < -127 ? -127 : v > 127 ? 127 : v;
}

/* lines [pan]: positive lines scroll up, positive pan scrolls right. */
static const char *cmd_wheel(struct run *r, char *args)
{
	long lines, pan = 0;

	if (!parse_long(&args, &lines) || (!at_end(args) && !parse_long(&args, &pan)) || !at_end(args)) {
		return "err bad args";
	}
	lines = clamp8(lines);
	pan = clamp8(pan);
	long steps = labs(lines) > labs(pan) ? labs(lines) : labs(pan);

	/* iOS ignores the size of a wheel report and a lone report, so a turn goes out as single detents. */
	r->total = steps;
	for (long i = 0; i < steps; i++) {
		int8_t v = i < labs(lines) ? (lines > 0 ? 1 : -1) : 0;
		int8_t h = i < labs(pan) ? (pan > 0 ? 1 : -1) : 0;
		uint8_t rep[MOUSE_LEN] = {0, 0, 0, (uint8_t)v, (uint8_t)h};

		if (i) {
			wait_ms(r, WHEEL_STEP_MS);
		}
		put(r, REP_MOUSE, rep, sizeof(rep));
	}
	return outcome(r);
}

static const char *cmd_text(struct run *r, char *args)
{
	char text[PROTO_LINE_MAX];
	bool unsupported;
	struct key k;

	if (!decode_json(args, text, sizeof(text), &unsupported)) {
		return "err bad json";
	}
	for (const char *c = text; *c; c++) {
		if (unsupported || !char_key(*c, &k)) {
			return "err unsupported char";
		}
	}
	r->total = 2 * strlen(text);
	for (const char *c = text; *c && !r->err; c++) {
		char_key(*c, &k);
		press_key(r, k);
	}
	return outcome(r);
}

static const char *cmd_key(struct run *r, char *args)
{
	struct key k;

	if (!parse_combo(args, &k)) {
		return "err unsupported key";
	}
	r->total = 2;
	press_key(r, k);
	return outcome(r);
}

static const char *cmd_media(struct run *r, char *args)
{
	for (size_t i = 0; i < sizeof(media_names) / sizeof(media_names[0]); i++) {
		if (strcmp(media_names[i].name, args) == 0) {
			r->total = 2;
			consumer(r, media_names[i].usage);
			consumer(r, 0);
			return outcome(r);
		}
	}
	return "err unsupported media";
}

static const char *cmd_pointer(struct run *r, char *args)
{
	long b, x, y;

	if (!parse_long(&args, &b) || !parse_long(&args, &x) || !parse_long(&args, &y) || !at_end(args)) {
		return "err bad args";
	}
	r->total = 1;
	pointer(r, b, x < 0 ? 0 : x > POINTER_MAX ? POINTER_MAX : x, y < 0 ? 0 : y > POINTER_MAX ? POINTER_MAX : y);
	return outcome(r);
}

/* A v1 line of numbers: 1 is a consumer usage, 3 a relative mouse report, 8 a keyboard report. */
static const char *cmd_numbers(struct run *r, char *args)
{
	long v[8];
	int n = 0;

	while (n < 8 && parse_long(&args, &v[n])) {
		n++;
	}
	if (!at_end(args)) {
		return "err bad args";
	}
	r->total = 1;
	if (n == 1) {
		consumer(r, v[0] < 0 ? 0 : v[0] > 0x3FF ? 0x3FF : v[0]);
	} else if (n == 3) {
		uint8_t rep[MOUSE_LEN] = {v[0], (uint8_t)clamp8(v[1]), (uint8_t)clamp8(v[2])};

		put(r, REP_MOUSE, rep, sizeof(rep));
	} else if (n == 8) {
		uint8_t rep[KEYS_LEN];

		for (int i = 0; i < KEYS_LEN; i++) {
			rep[i] = v[i];
		}
		put(r, REP_KEYS, rep, sizeof(rep));
	} else {
		return "err bad args";
	}
	return outcome(r);
}

static const char *cmd_reset(const struct proto_ops *ops)
{
	if (ops->hid_init_err || ops->ready()) {
		return "ok";
	}
	struct run r = {.ops = ops, .total = 4};
	uint8_t keys[KEYS_LEN] = {0};
	uint8_t mouse[MOUSE_LEN] = {0};

	put(&r, REP_KEYS, keys, sizeof(keys));
	put(&r, REP_MOUSE, mouse, sizeof(mouse));
	consumer(&r, 0);
	if (touch_mode) {
		contact(&r, false, pointer_x, pointer_y);
	} else {
		pointer(&r, 0, pointer_x, pointer_y);
	}
	return outcome(&r);
}

static const char *cmd_mode(char *args)
{
	if (!*args) {
		return touch_mode ? "ok touch" : "ok pointer";
	}
	if (strcmp(args, "touch") == 0 || strcmp(args, "pointer") == 0) {
		touch_mode = args[0] == 't';
		touching = false;
		return "ok";
	}
	return "err bad args";
}

static const char *cmd_result(char *args)
{
	for (int i = 0; i < RESULT_SLOTS; i++) {
		if (results[i].id[0] && strcmp(results[i].id, args) == 0) {
			return results[i].reply;
		}
	}
	return "err unknown id";
}

static const char *done(int err)
{
	static char data[PROTO_REPLY_MAX];

	if (!err) {
		return "ok";
	}
	snprintf(data, sizeof(data), "err failed %d", err);
	return data;
}

static const char *host_addr(const struct proto_hosts *h, int index, const char *missing)
{
	return index >= 0 && index < h->count ? h->list[index].addr : missing;
}

static const char *cmd_hosts(const struct proto_ops *ops)
{
	static char data[PROTO_REPLY_MAX];
	struct proto_hosts h;

	ops->hosts(&h);
	snprintf(data, sizeof(data), "ok count=%d use=%s conn=%s", h.count, host_addr(&h, h.chosen, "any"),
		 host_addr(&h, h.connected, "none"));
	return data;
}

static const char *cmd_host(const struct proto_ops *ops, char *args)
{
	static char data[PROTO_REPLY_MAX];
	struct proto_hosts h;
	char *end;
	long index = strtol(args, &end, 10);

	ops->hosts(&h);
	if (!*args || *end || index < 0 || index >= h.count) {
		return "err bad args";
	}
	snprintf(data, sizeof(data), "ok addr=%s name=%s", h.list[index].addr, h.list[index].name);
	return data;
}

static bool same_addr(const char *a, const char *b)
{
	while (*a && toupper((unsigned char)*a) == toupper((unsigned char)*b)) {
		a++;
		b++;
	}
	return *a == *b;
}

static const char *cmd_use(const struct proto_ops *ops, char *args)
{
	struct proto_hosts h;

	if (strcmp(args, "any") == 0) {
		return done(ops->use(-1));
	}
	ops->hosts(&h);
	for (int i = 0; i < h.count; i++) {
		if (same_addr(h.list[i].addr, args)) {
			return done(ops->use(i));
		}
	}
	return "err unknown host";
}

static const struct {
	const char *verb;
	const char *(*run)(struct run *r, char *args);
} report_verbs[] = {
	{"tap", cmd_tap}, {"hold", cmd_hold}, {"move", cmd_move}, {"swipe", cmd_swipe}, {"wheel", cmd_wheel},
	{"text", cmd_text}, {"key", cmd_key}, {"media", cmd_media}, {"pointer", cmd_pointer}, {"a", cmd_pointer},
	{"", cmd_numbers},
};

static const char *dispatch(const struct proto_ops *ops, const char *verb, char *args)
{
	static char data[PROTO_REPLY_MAX];

	if (strcmp(verb, "version") == 0) {
		ops->confirm();
		snprintf(data, sizeof(data), "ok airhand %s id=%s", PROTO_VERSION, ops->chip_id);
		return data;
	}
	if (strcmp(verb, "status") == 0) {
		char status[PROTO_REPLY_MAX - 4];

		ops->status(status, sizeof(status));
		snprintf(data, sizeof(data), "ok %s", status);
		return data;
	}
	if (strcmp(verb, "unpair") == 0) {
		return done(ops->unpair());
	}
	if (strcmp(verb, "update") == 0) {
		return done(ops->update());
	}
	if (strcmp(verb, "reset") == 0) {
		return cmd_reset(ops);
	}
	if (strcmp(verb, "mode") == 0) {
		return cmd_mode(args);
	}
	if (strcmp(verb, "result") == 0) {
		return cmd_result(args);
	}
	if (strcmp(verb, "hosts") == 0) {
		return cmd_hosts(ops);
	}
	if (strcmp(verb, "host") == 0) {
		return cmd_host(ops, args);
	}
	if (strcmp(verb, "use") == 0) {
		return cmd_use(ops, args);
	}
	for (size_t i = 0; i < sizeof(report_verbs) / sizeof(report_verbs[0]); i++) {
		if (strcmp(report_verbs[i].verb, verb) == 0) {
			const char *refused = refusal(ops);
			struct run r = {.ops = ops};

			return refused ? refused : report_verbs[i].run(&r, args);
		}
	}
	return "err unknown verb";
}

static bool is_id(const char *word, size_t len)
{
	if (len == 0 || len > ID_MAX) {
		return false;
	}
	for (size_t i = 0; i < len; i++) {
		if (!isdigit((unsigned char)word[i])) {
			return false;
		}
	}
	return true;
}

static void remember(const char *id, const char *status)
{
	strncpy(results[next_slot].id, id, ID_MAX);
	results[next_slot].id[ID_MAX] = '\0';
	strncpy(results[next_slot].reply, status, PROTO_REPLY_MAX - 1);
	results[next_slot].reply[PROTO_REPLY_MAX - 1] = '\0';
	next_slot = (next_slot + 1) % RESULT_SLOTS;
}

const char *proto_handle(const struct proto_ops *ops, const char *line)
{
	static char out[PROTO_REPLY_MAX + ID_MAX + 2];
	char buf[PROTO_LINE_MAX];
	char id[ID_MAX + 1] = "0";
	char *verb = buf;
	char *args;
	size_t first;

	if (strlen(line) >= sizeof(buf)) {
		const char *space = strchr(line, ' ');

		if (space && is_id(line, space - line)) {
			snprintf(out, sizeof(out), "%.*s err line too long", (int)(space - line), line);
		} else {
			snprintf(out, sizeof(out), "0 err line too long");
		}
		return out;
	}
	strcpy(buf, line);
	while (*verb == ' ') {
		verb++;
	}
	if (!*verb) {
		return "";
	}
	first = strcspn(verb, " ");
	if (verb[first] == ' ' && is_id(verb, first) && isalpha((unsigned char)verb[first + 1])) {
		memcpy(id, verb, first);
		id[first] = '\0';
		verb += first + 1;
	}
	if (isalpha((unsigned char)*verb)) {
		size_t len = strcspn(verb, " ");

		args = verb + len;
		if (*args) {
			*args++ = '\0';
		}
	} else {
		args = verb;
		verb = "";
	}

	const char *status = dispatch(ops, verb, args);

	if (strcmp(id, "0") != 0 && strcmp(verb, "result") != 0) {
		remember(id, status);
	}
	snprintf(out, sizeof(out), "%s %s", id, status);
	return out;
}
```

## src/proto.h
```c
/*
 * The serial protocol, free of Zephyr so the host tests can build it.
 * A request is "<id> <verb> [args]" and gets exactly one reply, "<id> ok [data]" or "<id> err <reason>".
 */
#ifndef AIRHAND_PROTO_H
#define AIRHAND_PROTO_H

#include <stddef.h>
#include <stdint.h>

#define PROTO_LINE_MAX 256
#define PROTO_REPLY_MAX 160
#ifndef PROTO_VERSION
#error "PROTO_VERSION comes from firmware/VERSION"
#endif

enum proto_report { REP_KEYS, REP_MOUSE, REP_CONSUMER, REP_POINTER, REP_TOUCH };

#define KEYS_LEN 8
#define MOUSE_LEN 5
#define CONSUMER_LEN 2
#define POINTER_LEN 5
#define TOUCH_LEN 7
#define WIN8_LEN 1
#define POINTER_MAX 0x7FFF
#define PROTO_HOSTS_MAX 4
#define PROTO_ADDR_LEN 17
#define PROTO_NAME_MAX 32

struct proto_host {
	char addr[PROTO_ADDR_LEN + 1];
	char name[PROTO_NAME_MAX + 1];
};

/* chosen and connected are indexes into list, -1 for any host and for none. */
struct proto_hosts {
	int count;
	int chosen;
	int connected;
	struct proto_host list[PROTO_HOSTS_MAX];
};

struct proto_ops {
	/* 0 when a host can take reports, -ENOTCONN without a host, -EACCES on a link that is not encrypted. */
	int (*ready)(void);
	/* 0 when the stack queued the report, a negative errno otherwise. */
	int (*send)(enum proto_report report, const uint8_t *data, size_t len);
	void (*sleep_ms)(uint32_t ms);
	int (*unpair)(void);
	void (*status)(char *out, size_t len);
	/* Marks the running image good, so MCUboot keeps it; called on every version request. */
	void (*confirm)(void);
	/* Reboots into the bootloader's update mode once the reply is out; 0, or a negative errno. */
	int (*update)(void);
	const char *chip_id;
	int hid_init_err;
	void (*hosts)(struct proto_hosts *out);
	/* Lets only list[index] of hosts() connect and drops any other; -1 lets every paired host connect again. */
	int (*use)(int index);
};

/* Runs one line; returns the reply line without its newline. Empty lines get no reply (an empty string). */
const char *proto_handle(const struct proto_ops *ops, const char *line);

#endif
```
